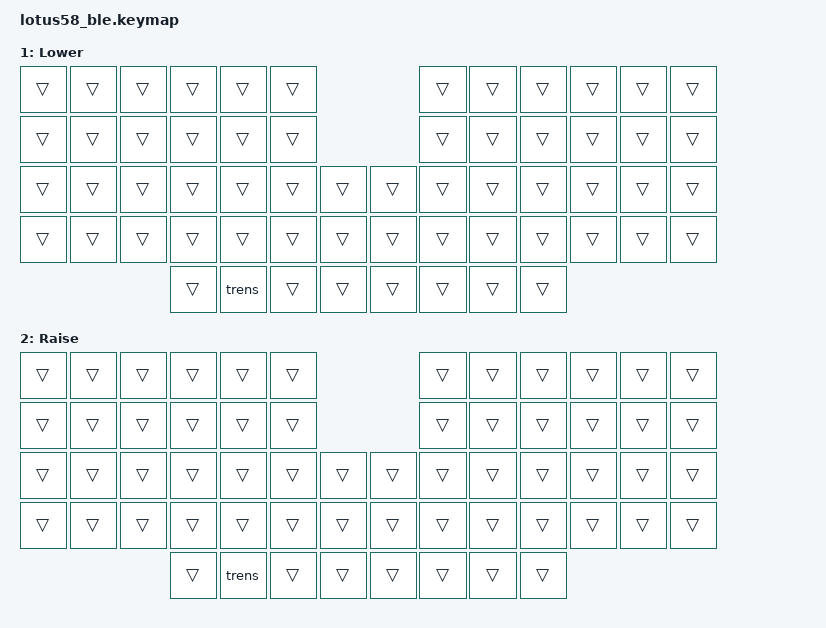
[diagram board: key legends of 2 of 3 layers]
/*
 * Copyright (c) 2024 Allister MacLeod
 * SPDX-License-Identifier: MIT
 */

#include <behaviors.dtsi>
#include <dt-bindings/zmk/keys.h>
#include <dt-bindings/zmk/bt.h>
#include <dt-bindings/zmk/outputs.h>

/ {
    keymap {
        compatible = "zmk,keymap";

        default_layer {
            bindings = <
&kp ESC   &kp N1 &kp N2 &kp N3   &kp N4   &kp N5                       &kp N6 &kp N7   &kp N8    &kp N9  &kp N0   &kp BSPC
&kp TAB   &kp Q  &kp W  &kp E    &kp R    &kp T                        &kp Y  &kp U    &kp I     &kp O   &kp P    &kp BSLH
&kp LSHFT &kp A  &kp S  &kp D    &kp F    &kp G  &sys_reset &sys_reset &kp H  &kp J    &kp K     &kp L   &kp SCLN &kp ENTER
&kp LCTRL &kp Z  &kp X  &kp C    &kp V    &kp B  &kp LBKT   &kp RBKT   &kp N  &kp M    &kp COMMA &kp DOT &kp FSLH &kp RCTRL
                        &kp LGUI &kp LALT &mo 1  &kp SPACE  &kp SPACE  &mo 2  &kp BSPC &kp LALT  &kp RGUI
            >;
            sensor-bindings = <
                &inc_dec_kp A B
                &inc_dec_kp X Y
            >;
            display-name = "QWERTY";
        };

        lower_layer {
            bindings = <
&trans &trans &trans &trans &trans &trans                  &trans &trans &trans &trans &trans &trans
&trans &trans &trans &trans &trans &trans                  &trans &trans &trans &trans &trans &trans
&trans &trans &trans &trans &trans &trans &trans    &trans &trans &trans &trans &trans &trans &trans
&trans &trans &trans &trans &trans &trans &trans    &trans &trans &trans &trans &trans &trans &trans
                     &trans &trens &trans &trans    &trans &trans &trans &trans
            >;
            sensor-bindings = <
                &inc_dec_kp A B
                &inc_dec_kp X Y
            >;
            display-name = "Lower";
        };

        raise_layer {
            bindings = <
&trans &trans &trans &trans &trans &trans                  &trans &trans &trans &trans &trans &trans
&trans &trans &trans &trans &trans &trans                  &trans &trans &trans &trans &trans &trans
&trans &trans &trans &trans &trans &trans &trans    &trans &trans &trans &trans &trans &trans &trans
&trans &trans &trans &trans &trans &trans &trans    &trans &trans &trans &trans &trans &trans &trans
                     &trans &trens &trans &trans    &trans &trans &trans &trans
            >;
            sensor-bindings = <
                &inc_dec_kp A B
                &inc_dec_kp X Y
            >;
            display-name = "Raise";
        };
    };
};
